BO_ 96 GAS: 64 XXX
 SG_ GAS_POSITION : 79|8@0+ (0.0039370078,0) [0|255] "%" XXX

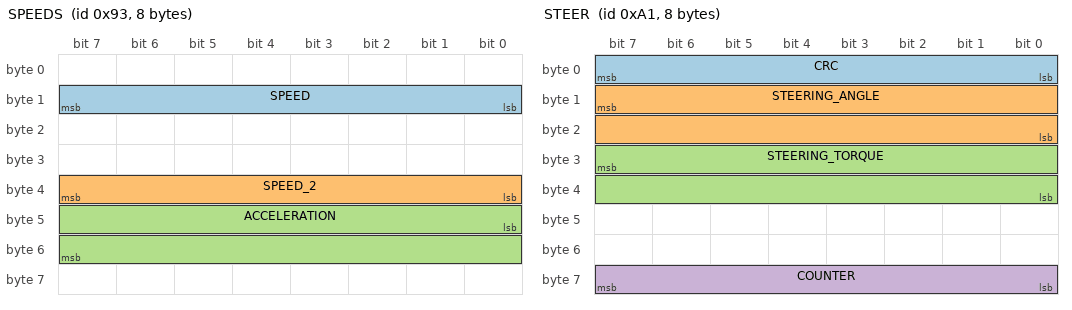
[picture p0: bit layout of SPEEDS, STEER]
BO_ 147 SPEEDS: 8 XXX
 SG_ SPEED : 15|8@0+ (3.5,0) [0|255] "kph" XXX
 SG_ SPEED_2 : 39|8@0+ (1,0) [0|255] "??" XXX
 SG_ ACCELERATION : 40|16@1+ (1,0) [0|65535] "??" XXX

BO_ 161 STEER: 8 XXX
 SG_ CRC : 7|8@0+ (1,0) [0|255] "" XXX
 SG_ STEERING_ANGLE : 15|16@0+ (0.05,0) [0|65535] "degs" XXX
 SG_ STEERING_TORQUE : 31|16@0+ (1,0) [0|65535] "??" XXX
 SG_ COUNTER : 63|8@0+ (1,0) [0|255] "" XXX

BO_ 288 BRAKE: 64 XXX
 SG_ BRAKE_SIGNAL1 : 15|8@0+ (1,0) [0|255] "" XXX
 SG_ BRAKE_PRESSURE : 39|8@0+ (1,-25) [0|255] "" XXX
 SG_ BRAKE_SIGNAL2 : 47|8@0+ (1,0) [0|255] "" XXX

BO_ 311 HANDBRAKE: 64 XXX
 SG_ HANDBRAKE_RELEASED : 153|1@0+ (1,0) [0|1] "" XXX
 SG_ HANDBRAKE_ENABLED : 154|1@0+ (1,0) [0|1] "" XXX

BO_ 315 WHEEL_SPEEDS: 64 XXX
 SG_ LEFT_WHEEL_RPM : 12|13@0+ (1,0) [0|8191] "" XXX
 SG_ RIGHT_WHEEL_RPM : 28|13@0+ (1,0) [0|8191] "" XXX
 SG_ DISTANCE_ACCUMULATOR : 47|16@0+ (1,0) [0|65535] "??" XXX

BO_ 412 LIGHTS: 16 XXX
 SG_ RIGHT_TURN_SIGNAL : 30|1@0+ (1,0) [0|1] "" XXX
 SG_ LEFT_TURN_SIGNAL : 31|1@0+ (1,0) [0|1] "" XXX

BO_ 573 ACCELEROMETER: 64 XXX
 SG_ COUNTER : 187|12@0+ (1,0) [0|4095] "" XXX
 SG_ ACCELEROMETER : 207|8@0+ (1,0) [0|255] "" XXX

BO_ 649 DOOR_PAX_LEFT: 64 XXX
 SG_ DOOR_FRONTAL_PAX_OPEN : 382|1@0+ (1,0) [0|1] "" XXX
 SG_ DOOR_FRONTAL_PAX_CLOSED : 383|1@0+ (1,0) [0|1] "" XXX

BO_ 793 DOOR_DRIVER: 16 XXX
 SG_ DOOR_DRIVER_OPEN : 22|1@0+ (1,0) [0|1] "" XXX

BO_ 849 SEATBELT_OR_SAFETY: 16 XXX
 SG_ SEAT_BELT_DRIVER_OR_SAFETY_SIGNAL1 : 11|1@0+ (1,0) [0|1] "" XXX
 SG_ SEAT_BELT_DRIVER_OR_SAFETY_SIGNAL2 : 24|1@0+ (1,0) [0|1] "" XXX

CM_ SG_ 96 GAS_POSITION "0 - 1 (1=100%)";
CM_ SG_ 147 SPEED "lower precision";
CM_ SG_ 147 ACCELERATION "??";
CM_ SG_ 161 STEERING_ANGLE "0 CENTER, NO LEFT / RIGHT SIGNAL";
CM_ SG_ 161 STEERING_TORQUE "Peak lef 3680, 0 = stopped";
CM_ SG_ 288 BRAKE_SIGNAL1 "DOUBT 114 WHEN MOVING";
CM_ SG_ 315 DISTANCE_ACCUMULATOR "?? doubts";
CM_ BO_ 573 "??";
CM_ BO_ 649 "FRONT";
